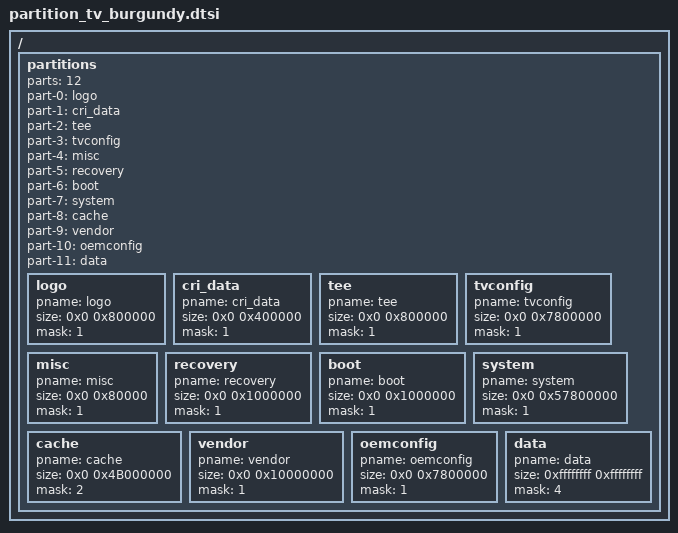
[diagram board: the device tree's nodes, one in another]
/*
 * Amlogic partition set for normal
 *
 * Copyright (c) 2017-2017 Amlogic Ltd
 *
 * This file is licensed under a dual GPLv2 or BSD license.
 *
 */
 / {
    partitions: partitions{
        parts = <12>;
		part-0 = <&logo>;
		part-1 = <&cri_data>;
		part-2 = <&tee>;
		part-3 = <&tvconfig>;
		part-4 = <&misc>;
		part-5 = <&recovery>;
		part-6 = <&boot>;
		part-7 = <&system>;
		part-8 = <&cache>;
		part-9 = <&vendor>;
		part-10 = <&oemconfig>;
		part-11 = <&data>;

		logo:logo{
			pname = "logo";
			size = <0x0 0x800000>;
			mask = <1>;
		};
		cri_data:cri_data
		{
			pname = "cri_data";
			size = <0x0 0x400000>;
			mask = <1>;
		};
		tee:tee{
			pname = "tee";
			size = <0x0 0x800000>;
			mask = <1>;
		};
		tvconfig:tvconfig{
			pname = "tvconfig";
			size = <0x0 0x7800000>;
			mask = <1>;
		};
		misc:misc{
			pname = "misc";
			size = <0x0 0x80000>;
			mask = <1>;
		};
		recovery:recovery{
			pname = "recovery";
			size = <0x0 0x1000000>;
			mask = <1>;
		};
		boot:boot
		{
			pname = "boot";
			size = <0x0 0x1000000>;
			mask = <1>;
		};
		system:system
		{
			pname = "system";
			size = <0x0 0x57800000>;
			mask = <1>;
		};
		cache:cache
		{
			pname = "cache";
			size = <0x0 0x4B000000>;
			mask = <2>;
		};
		vendor:vendor
		{
			pname = "vendor";
			size = <0x0 0x10000000>;
			mask = <1>;
		};
		oemconfig:oemconfig{
                        pname = "oemconfig";
                        size = <0x0 0x7800000>;
                        mask = <1>;
                };
		data:data
		{
			pname = "data";
			size = <0xffffffff 0xffffffff>;
			mask = <4>;
		};
	};
 };/* end of / */
